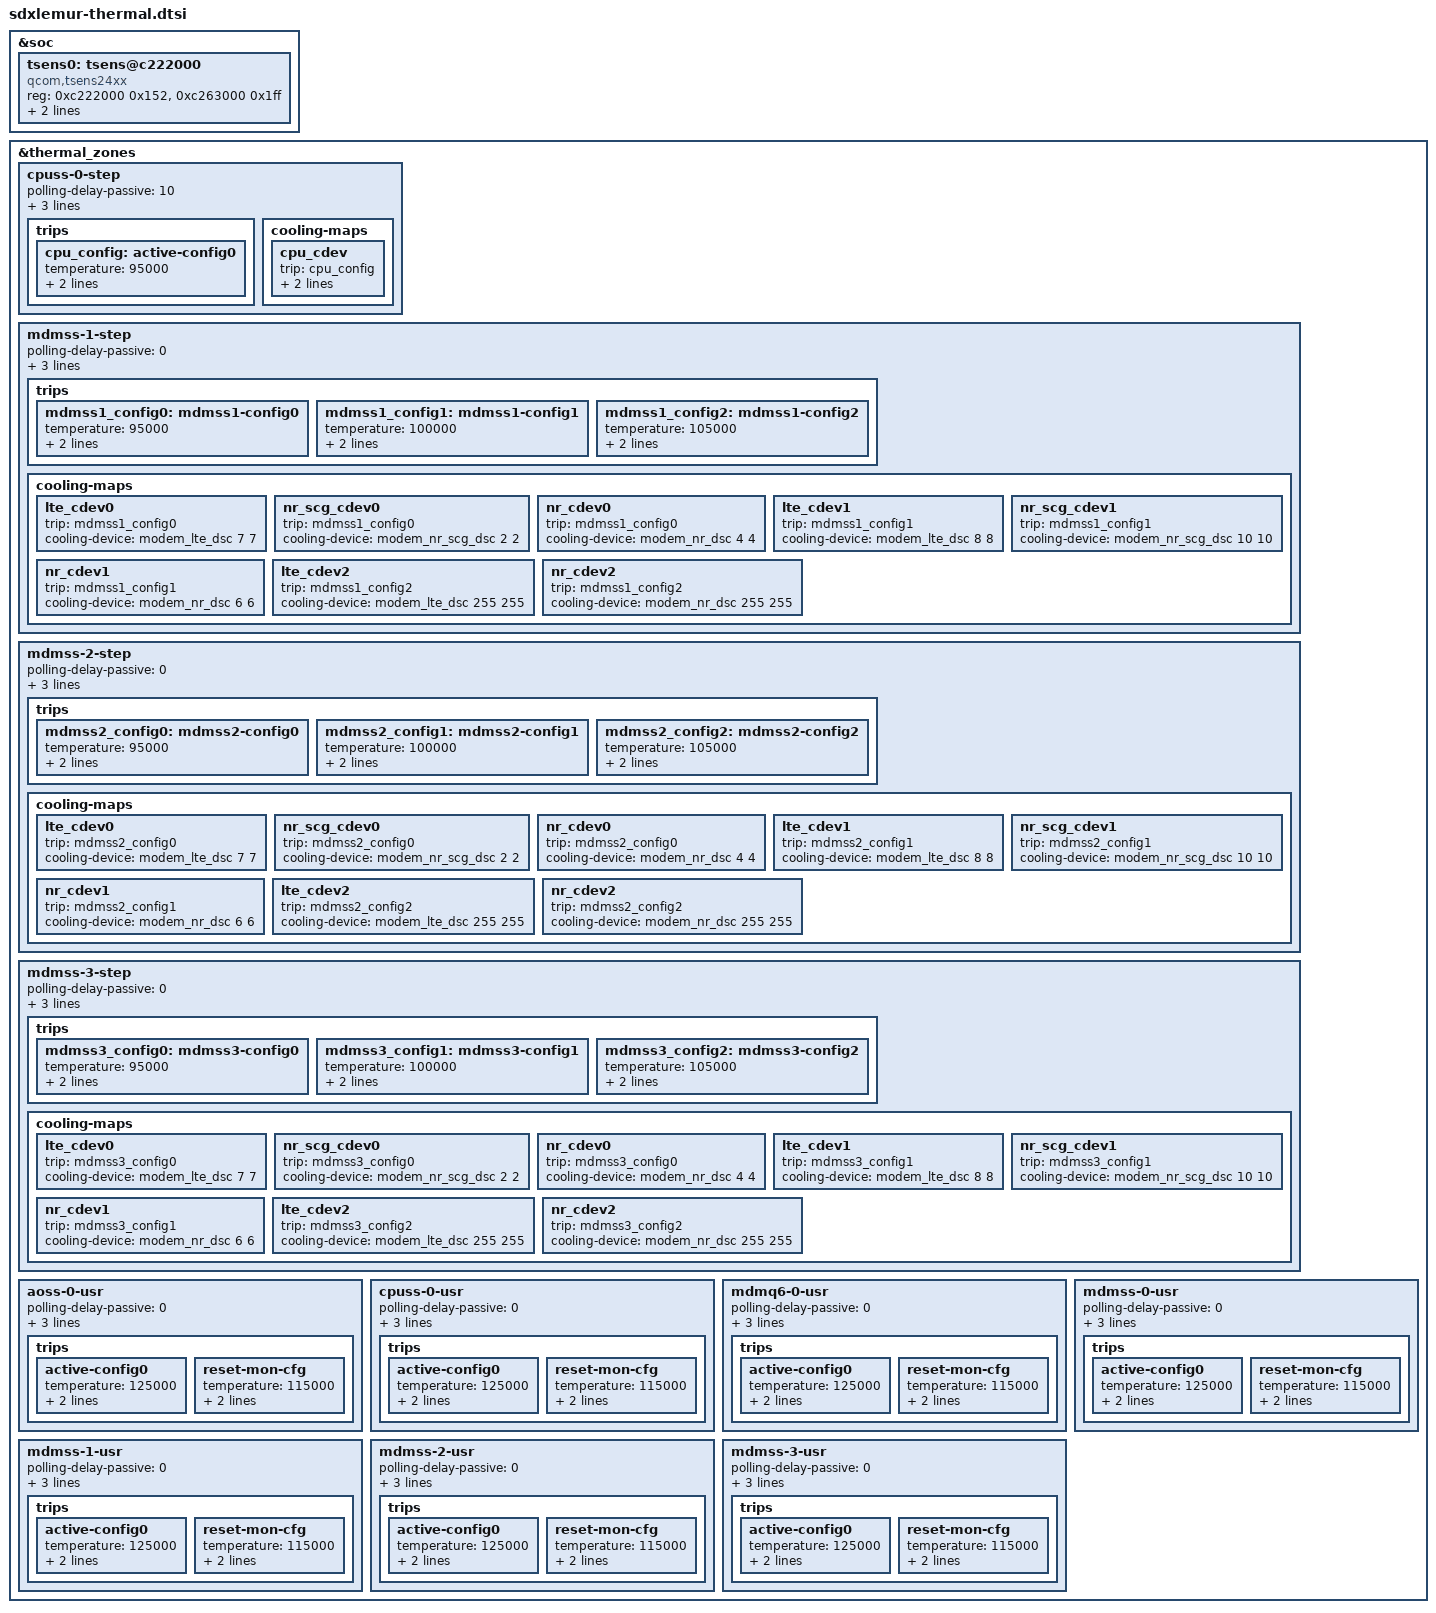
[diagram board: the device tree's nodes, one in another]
#include <dt-bindings/thermal/thermal_qti.h>

&soc {
	tsens0: tsens@c222000 {
		compatible = "qcom,tsens24xx";
		reg = <0xc222000 0x152>,
			<0xc263000 0x1ff>;
		reg-names = "tsens_srot_physical",
				"tsens_tm_physical";
		interrupts = <GIC_SPI 160 IRQ_TYPE_LEVEL_HIGH>,
				<GIC_SPI 161 IRQ_TYPE_LEVEL_HIGH>;
		interrupt-names = "tsens-upper-lower", "tsens-critical";
		#thermal-sensor-cells = <1>;
	};
};

#include "sdxlemur-thermal-modem.dtsi"

&thermal_zones {
	cpuss-0-step {
		polling-delay-passive = <10>;
		polling-delay = <0>;
		thermal-governor = "step_wise";
		thermal-sensors = <&tsens0 1>;
		trips {
			cpu_config: active-config0 {
				temperature = <95000>;
				hysteresis = <0>;
				type = "passive";
			};
		};

		cooling-maps {
			cpu_cdev {
				trip = <&cpu_config>;
				cooling-device = <&CPU0 THERMAL_NO_LIMIT
							THERMAL_NO_LIMIT>;
			};
		};
	};

	mdmss-1-step {
		polling-delay-passive = <0>;
		polling-delay = <0>;
		thermal-governor = "step_wise";
		thermal-sensors = <&tsens0 3>;
		trips {
			mdmss1_config0: mdmss1-config0 {
				temperature = <95000>;
				hysteresis = <5000>;
				type = "passive";
			};

			mdmss1_config1: mdmss1-config1 {
				temperature = <100000>;
				hysteresis = <5000>;
				type = "passive";
			};

			mdmss1_config2: mdmss1-config2 {
				temperature = <105000>;
				hysteresis = <5000>;
				type = "passive";
			};
		};

		cooling-maps {
			lte_cdev0 {
				trip = <&mdmss1_config0>;
				cooling-device = <&modem_lte_dsc 7 7>;
			};

			nr_scg_cdev0 {
				trip = <&mdmss1_config0>;
				cooling-device = <&modem_nr_scg_dsc 2 2>;
			};

			nr_cdev0 {
				trip = <&mdmss1_config0>;
				cooling-device = <&modem_nr_dsc 4 4>;
			};

			lte_cdev1 {
				trip = <&mdmss1_config1>;
				cooling-device = <&modem_lte_dsc 8 8>;
			};

			nr_scg_cdev1 {
				trip = <&mdmss1_config1>;
				cooling-device = <&modem_nr_scg_dsc 10 10>;
			};

			nr_cdev1 {
				trip = <&mdmss1_config1>;
				cooling-device = <&modem_nr_dsc 6 6>;
			};

			lte_cdev2 {
				trip = <&mdmss1_config2>;
				cooling-device = <&modem_lte_dsc 255 255>;
			};

			nr_cdev2 {
				trip = <&mdmss1_config2>;
				cooling-device = <&modem_nr_dsc 255 255>;
			};
		};
	};

	mdmss-2-step {
		polling-delay-passive = <0>;
		polling-delay = <0>;
		thermal-governor = "step_wise";
		thermal-sensors = <&tsens0 4>;
		trips {
			mdmss2_config0: mdmss2-config0 {
				temperature = <95000>;
				hysteresis = <5000>;
				type = "passive";
			};

			mdmss2_config1: mdmss2-config1 {
				temperature = <100000>;
				hysteresis = <5000>;
				type = "passive";
			};

			mdmss2_config2: mdmss2-config2 {
				temperature = <105000>;
				hysteresis = <5000>;
				type = "passive";
			};
		};

		cooling-maps {
			lte_cdev0 {
				trip = <&mdmss2_config0>;
				cooling-device = <&modem_lte_dsc 7 7>;
			};

			nr_scg_cdev0 {
				trip = <&mdmss2_config0>;
				cooling-device = <&modem_nr_scg_dsc 2 2>;
			};

			nr_cdev0 {
				trip = <&mdmss2_config0>;
				cooling-device = <&modem_nr_dsc 4 4>;
			};

			lte_cdev1 {
				trip = <&mdmss2_config1>;
				cooling-device = <&modem_lte_dsc 8 8>;
			};

			nr_scg_cdev1 {
				trip = <&mdmss2_config1>;
				cooling-device = <&modem_nr_scg_dsc 10 10>;
			};

			nr_cdev1 {
				trip = <&mdmss2_config1>;
				cooling-device = <&modem_nr_dsc 6 6>;
			};

			lte_cdev2 {
				trip = <&mdmss2_config2>;
				cooling-device = <&modem_lte_dsc 255 255>;
			};

			nr_cdev2 {
				trip = <&mdmss2_config2>;
				cooling-device = <&modem_nr_dsc 255 255>;
			};
		};
	};

	mdmss-3-step {
		polling-delay-passive = <0>;
		polling-delay = <0>;
		thermal-governor = "step_wise";
		thermal-sensors = <&tsens0 5>;
		trips {
			mdmss3_config0: mdmss3-config0 {
				temperature = <95000>;
				hysteresis = <5000>;
				type = "passive";
			};

			mdmss3_config1: mdmss3-config1 {
				temperature = <100000>;
				hysteresis = <5000>;
				type = "passive";
			};

			mdmss3_config2: mdmss3-config2 {
				temperature = <105000>;
				hysteresis = <5000>;
				type = "passive";
			};
		};

		cooling-maps {
			lte_cdev0 {
				trip = <&mdmss3_config0>;
				cooling-device = <&modem_lte_dsc 7 7>;
			};

			nr_scg_cdev0 {
				trip = <&mdmss3_config0>;
				cooling-device = <&modem_nr_scg_dsc 2 2>;
			};

			nr_cdev0 {
				trip = <&mdmss3_config0>;
				cooling-device = <&modem_nr_dsc 4 4>;
			};

			lte_cdev1 {
				trip = <&mdmss3_config1>;
				cooling-device = <&modem_lte_dsc 8 8>;
			};

			nr_scg_cdev1 {
				trip = <&mdmss3_config1>;
				cooling-device = <&modem_nr_scg_dsc 10 10>;
			};

			nr_cdev1 {
				trip = <&mdmss3_config1>;
				cooling-device = <&modem_nr_dsc 6 6>;
			};

			lte_cdev2 {
				trip = <&mdmss3_config2>;
				cooling-device = <&modem_lte_dsc 255 255>;
			};

			nr_cdev2 {
				trip = <&mdmss3_config2>;
				cooling-device = <&modem_nr_dsc 255 255>;
			};
		};
	};

	aoss-0-usr {
		polling-delay-passive = <0>;
		polling-delay = <0>;
		thermal-governor = "user_space";
		thermal-sensors = <&tsens0 0>;
		trips {
			active-config0 {
				temperature = <125000>;
				hysteresis = <1000>;
				type = "passive";
			};

			reset-mon-cfg {
				temperature = <115000>;
				hysteresis = <5000>;
				type = "passive";
			};
		};
	};

	cpuss-0-usr {
		polling-delay-passive = <0>;
		polling-delay = <0>;
		thermal-governor = "user_space";
		thermal-sensors = <&tsens0 1>;
		trips {
			active-config0 {
				temperature = <125000>;
				hysteresis = <1000>;
				type = "passive";
			};

			reset-mon-cfg {
				temperature = <115000>;
				hysteresis = <5000>;
				type = "passive";
			};
		};
	};

	mdmq6-0-usr {
		polling-delay-passive = <0>;
		polling-delay = <0>;
		thermal-governor = "user_space";
		thermal-sensors = <&tsens0 2>;
		trips {
			active-config0 {
				temperature = <125000>;
				hysteresis = <1000>;
				type = "passive";
			};

			reset-mon-cfg {
				temperature = <115000>;
				hysteresis = <5000>;
				type = "passive";
			};
		};
	};

	mdmss-0-usr {
		polling-delay-passive = <0>;
		polling-delay = <0>;
		thermal-governor = "user_space";
		thermal-sensors = <&tsens0 3>;
		trips {
			active-config0 {
				temperature = <125000>;
				hysteresis = <1000>;
				type = "passive";
			};

			reset-mon-cfg {
				temperature = <115000>;
				hysteresis = <5000>;
				type = "passive";
			};
		};
	};

	mdmss-1-usr {
		polling-delay-passive = <0>;
		polling-delay = <0>;
		thermal-governor = "user_space";
		thermal-sensors = <&tsens0 4>;
		trips {
			active-config0 {
				temperature = <125000>;
				hysteresis = <1000>;
				type = "passive";
			};

			reset-mon-cfg {
				temperature = <115000>;
				hysteresis = <5000>;
				type = "passive";
			};
		};
	};

	mdmss-2-usr {
		polling-delay-passive = <0>;
		polling-delay = <0>;
		thermal-governor = "user_space";
		thermal-sensors = <&tsens0 5>;
		trips {
			active-config0 {
				temperature = <125000>;
				hysteresis = <1000>;
				type = "passive";
			};

			reset-mon-cfg {
				temperature = <115000>;
				hysteresis = <5000>;
				type = "passive";
			};
		};
	};

	mdmss-3-usr {
		polling-delay-passive = <0>;
		polling-delay = <0>;
		thermal-governor = "user_space";
		thermal-sensors = <&tsens0 6>;
		trips {
			active-config0 {
				temperature = <125000>;
				hysteresis = <1000>;
				type = "passive";
			};

			reset-mon-cfg {
				temperature = <115000>;
				hysteresis = <5000>;
				type = "passive";
			};
		};
	};
};
